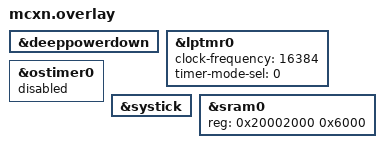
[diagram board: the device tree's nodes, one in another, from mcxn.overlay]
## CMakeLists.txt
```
# SPDX-FileCopyrightText: Copyright 2026 NXP
# SPDX-License-Identifier: Apache-2.0

cmake_minimum_required(VERSION 3.28.0)
find_package(Zephyr REQUIRED HINTS $ENV{ZEPHYR_BASE})
project(s2ram)

target_sources(app PRIVATE src/main.c)
```

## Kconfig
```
# SPDX-FileCopyrightText: Copyright 2026 NXP
# SPDX-License-Identifier: Apache-2.0

mainmenu "NXP MCX suspend-to-RAM sample"

choice
	prompt "Suspend-to-RAM wakeup source"
	default SAMPLE_S2RAM_WAKEUP_TIMER
	help
	  Select how the SoC is woken from suspend-to-RAM (Deep Power Down).

config SAMPLE_S2RAM_WAKEUP_TIMER
	bool "Timed wakeup"
	help
	  Wake after a fixed delay using a low-power timer.

config SAMPLE_S2RAM_WAKEUP_BUTTON
	bool "Button wakeup"
	help
	  Wake on a user button press.

endchoice

config SAMPLE_APP_TEST_CYCLES
	int "Number of suspend-to-RAM cycles to execute"
	range 1 1000
	default 10
	help
	  Number of times the sample suspends to RAM and resumes before it
	  stops. The retained cycle counter is checked against this value so
	  a test harness can confirm every wakeup happened.

source "Kconfig.zephyr"
```

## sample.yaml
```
# SPDX-FileCopyrightText: Copyright 2026 NXP
# SPDX-License-Identifier: Apache-2.0

sample:
  name: Suspend-to-RAM for NXP MCX

common:
  tags:
    - power
    - pm
  platform_allow:
    - frdm_mcxn947/mcxn947/cpu0
    - mcx_n5xx_evk/mcxn547/cpu0
    - mcx_n9xx_evk/mcxn947/cpu0
    - frdm_mcxn236
    - frdm_mcxa153
    - frdm_mcxa156
    - frdm_mcxa344
    - frdm_mcxa266
    - frdm_mcxa346
    - frdm_mcxa366
  integration_platforms:
    - frdm_mcxn947/mcxn947/cpu0
    - frdm_mcxa156
  harness: console
  harness_config:
    type: one_line
    regex:
      - "suspend-to-RAM demo"

tests:
  sample.boards.nxp.mcxn_a.s2ram.timer:
    timeout: 120
    harness_config:
      type: one_line
      regex:
        - "Completed 10 suspend-to-RAM cycles"
    extra_configs:
      - CONFIG_SAMPLE_S2RAM_WAKEUP_TIMER=y
  sample.boards.nxp.mcxn_a.s2ram.button:
    extra_configs:
      - CONFIG_SAMPLE_S2RAM_WAKEUP_BUTTON=y
```

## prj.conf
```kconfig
# SPDX-FileCopyrightText: Copyright 2026 NXP
# SPDX-License-Identifier: Apache-2.0

CONFIG_PM=y
CONFIG_WUC=y
CONFIG_COUNTER=y
CONFIG_COUNTER_MCUX_LPTMR_ALARM=y
```

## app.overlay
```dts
/*
 * SPDX-FileCopyrightText: Copyright 2026 NXP
 *
 * SPDX-License-Identifier: Apache-2.0
 */

/* Suspend-to-RAM (Deep Power Down) is opt-in: the SoC disables it by default.
 * This sample places its working set in retained RAM and arms a wakeup source,
 * so enable the state here.
 */
&deeppowerdown {
	status = "okay";
};

&lptmr0 {
	status = "okay";
	clock-frequency = <16384>;
	timer-mode-sel = <0>;
};

&ostimer0 {
	status = "disabled";
};

&systick {
	status = "okay";
};
```

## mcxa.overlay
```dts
/*
 * SPDX-FileCopyrightText: Copyright 2026 NXP
 *
 * SPDX-License-Identifier: Apache-2.0
 */

/* Suspend-to-RAM (Deep Power Down) is opt-in: the SoC disables it by default.
 * This sample places its working set in retained RAM and arms a wakeup source,
 * so enable the state here.
 */
&deeppowerdown {
	status = "okay";
};

&lptmr0 {
	clock-frequency = <16384>;
	timer-mode-sel = <0>;
	status = "okay";
};

&ostimer0 {
	status = "disabled";
};

&systick {
	status = "okay";
};
```

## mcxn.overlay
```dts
/*
 * SPDX-FileCopyrightText: Copyright 2026 NXP
 *
 * SPDX-License-Identifier: Apache-2.0
 */

/* Suspend-to-RAM (Deep Power Down) is opt-in: the SoC disables it by default.
 * This sample places its working set in retained RAM and arms a wakeup source,
 * so enable the state here.
 */
&deeppowerdown {
	status = "okay";
};

&lptmr0 {
	clock-frequency = <16384>;
	timer-mode-sel = <0>;
	status = "okay";
};

&ostimer0 {
	status = "disabled";
};

&systick {
	status = "okay";
};

/* Constrain zephyr,sram to RAMA1-RAMA3 (24 KB at 0x20002000) so the whole
 * retained working set is both kept across Deep Power Down and kept clear of
 * the boot ROM scratch.
 */
&sram0 {
	reg = <0x20002000 0x6000>;
};
```

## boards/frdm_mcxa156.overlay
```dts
/*
 * SPDX-FileCopyrightText: Copyright 2026 NXP
 *
 * SPDX-License-Identifier: Apache-2.0
 */

&ostimer0 {
	status = "disabled";
};

&systick {
	status = "okay";
};

/* Suspend-to-RAM is opt-in (the SoC disables it by default); enable it here. */
&deeppowerdown {
	status = "okay";
};
```

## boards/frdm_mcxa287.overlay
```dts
/*
 * SPDX-FileCopyrightText: Copyright 2026 NXP
 *
 * SPDX-License-Identifier: Apache-2.0
 */

/* Deep Power Down on MCXAxx7 can retain ONLY SRAM arrays A0 and A3 (per the
 * reference manual, section "Deep Power Down mode"). A1 and A2 lose power in
 * DPD regardless of the VBAT retention config. Constrain zephyr,sram to A3
 * (16 KB at 0x20004000) so the entire retained working set - including the
 * pm_s2ram marker and saved CPU context - lands in a DPD-retainable array.
 */
&sram0 {
	reg = <0x20004000 0x4000>;
};

/* Suspend-to-RAM is opt-in (the SoC disables it by default); enable it here. */
&deeppowerdown {
	status = "okay";
};
```

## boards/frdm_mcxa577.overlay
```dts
/*
 * SPDX-FileCopyrightText: Copyright 2026 NXP
 *
 * SPDX-License-Identifier: Apache-2.0
 */

/* Suspend-to-RAM (Deep Power Down) is opt-in: the SoC disables it by default.
 * This sample places its working set in retained RAM and arms a wakeup source,
 * so enable the state here.
 */
&deeppowerdown {
	status = "okay";
};

&lptmr0 {
	clock-frequency = <16384>;
	timer-mode-sel = <0>;
	status = "okay";
};

&ostimer0 {
	status = "disabled";
};

&systick {
	status = "okay";
};

/* Deep Power Down on MCXAxx7 can retain ONLY SRAM arrays A0 and A3 (per the
 * reference manual, section "Deep Power Down mode"). A1 and A2 lose power in
 * DPD regardless of the VBAT retention config. Constrain zephyr,sram to A3
 * (16 KB at 0x20004000) so the entire retained working set - including the
 * pm_s2ram marker and saved CPU context - lands in a DPD-retainable array.
 */
&sram0 {
	reg = <0x20004000 0x4000>;
};
```

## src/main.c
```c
/*
 * SPDX-FileCopyrightText: Copyright 2026 NXP
 *
 * SPDX-License-Identifier: Apache-2.0
 */

#include <zephyr/kernel.h>
#include <zephyr/device.h>
#include <zephyr/pm/pm.h>
#include <zephyr/pm/policy.h>
#include <zephyr/drivers/wuc.h>

#define WAKEUP_DELAY_S 3U

#define APP_STACK_SIZE 2048
#define APP_PRIORITY   5

/* Incremented before every suspend. Its value surviving the suspend/resume
 * cycle proves the RAM was retained while the CORE domain was powered down.
 */
static uint32_t cycles;

#define CONSOLE_NODE   DT_CHOSEN(zephyr_console)
#define CONSOLE_PARENT DT_PARENT(CONSOLE_NODE)

static const struct device *const console_dev = DEVICE_DT_GET(CONSOLE_NODE);
#if DT_NODE_HAS_COMPAT(CONSOLE_PARENT, nxp_lp_flexcomm)
#define HAS_FLEXCOMM_PARENT 1
static const struct device *const flexcomm_dev = DEVICE_DT_GET(CONSOLE_PARENT);
#endif

/*
 * Deep Power Down resets every CORE-domain peripheral. On a transparent resume
 * the SoC restores the CPU context and clocks, but the console UART driver has
 * no device pm hooks, so re-initialise it before printing. Three clock gates
 * that Deep Power Down switched off have to be re-opened, bottom up, before the
 * console can drive its pins again:
 *
 *   1. the PORT pin-mux controllers - their gate must be on for the LPUART
 *      pinctrl re-apply (step 3) to actually reach the pad-mux registers,
 *   2. the parent LP_FLEXCOMM - its init re-enables the peripheral clock gate
 *      and re-selects LPUART mode, then
 *   3. the LPUART itself - its init re-applies pinctrl and the baud/format.
 *
 * device_init() is a no-op on an already-initialised device, so clear the
 * initialised flag to force each driver to re-run its init against the reset
 * hardware. (A production driver would do this through a PM_DEVICE_ACTION_RESUME
 * handler instead.) printk keeps working once the LPUART is back: its console
 * output hook still points at the same device.
 */
#define REINIT_DEVICE(dev)				\
	do {						\
		(dev)->state->initialized = false;	\
		(void)device_init(dev);			\
	} while (0)

#define REINIT_PORT(node_id) REINIT_DEVICE(DEVICE_DT_GET(node_id));

static void resume_console(void)
{
	/* Re-open every PORT pin-mux clock gate that Deep Power Down closed. */
	DT_FOREACH_STATUS_OKAY(nxp_port_pinmux, REINIT_PORT)

#ifdef HAS_FLEXCOMM_PARENT
	REINIT_DEVICE(flexcomm_dev);
#endif
	REINIT_DEVICE(console_dev);
}

#if defined(CONFIG_SAMPLE_S2RAM_WAKEUP_BUTTON)
/* In real-world applications, the button's wake-up event should be handled
 * via the driver hook, allowing the application to directly wait for input
 * events without needing to consider the existence of WUU. However, due to
 * the current lack of hook handling, we use the PM notifier to handle the
 * wake-up event.
 */
static K_SEM_DEFINE(button_wakeup, 0, 1);
static const struct wuc_dt_spec button = WUC_DT_SPEC_GET(DT_ALIAS(wakeup_button));

static void on_pm_state_exit(enum pm_state state)
{
	if (state == PM_STATE_SUSPEND_TO_RAM) {
		k_sem_give(&button_wakeup);
	}
}

static struct pm_notifier button_pm_notifier = {
	.state_exit = on_pm_state_exit,
};
#else
/* The timer variant relies on LPTMR0, which the counter driver arms as a
 * wakeup source on its own.
 */
#endif /* CONFIG_SAMPLE_S2RAM_WAKEUP_BUTTON */

static void app_thread(void *p1, void *p2, void *p3)
{
	ARG_UNUSED(p1);
	ARG_UNUSED(p2);
	ARG_UNUSED(p3);

	while (cycles < CONFIG_SAMPLE_APP_TEST_CYCLES) {
		cycles++;

#if defined(CONFIG_SAMPLE_S2RAM_WAKEUP_BUTTON)
		printk("Entering suspend-to-RAM (cycle %u/%u); press SW2 to wake\n", cycles,
		       CONFIG_SAMPLE_APP_TEST_CYCLES);
#else
		printk("Entering suspend-to-RAM (cycle %u/%u); wake in %u s\n", cycles,
		       CONFIG_SAMPLE_APP_TEST_CYCLES, WAKEUP_DELAY_S);
#endif

		/* Let the UART finish shifting out the line above before DPD cuts its clock. */
		k_busy_wait(2000);

#if defined(CONFIG_SAMPLE_S2RAM_WAKEUP_BUTTON) &&				\
	(defined(CONFIG_SOC_SERIES_MCXAXX6) || defined(CONFIG_SOC_SERIES_MCXAXX7))
		/* MCXAxx6 / MCXAxx7 clear the WUU config on the DPD wakeup reset,
		 * so re-arm the button before each entry.
		 */
		(void)wuc_enable_wakeup_source_dt(&button);
#endif

		pm_state_force(0U, &(struct pm_state_info){PM_STATE_SUSPEND_TO_RAM, 0, 0});
#if defined(CONFIG_SAMPLE_S2RAM_WAKEUP_BUTTON)
		/* Block until SW2 wakes the SoC; the PM notifier gives this. */
		k_sem_take(&button_wakeup, K_FOREVER);
#else
		k_sleep(K_SECONDS(WAKEUP_DELAY_S));
#endif

		resume_console();
		printk("Resumed from suspend-to-RAM; retained counter is %u\n", cycles);
	}

	/* All threads are now idle for good, but every PM state is locked, so the
	 * SoC stays awake and the board remains debuggable after the test.
	 */
	printk("Completed %u suspend-to-RAM cycles\n", cycles);
}

K_THREAD_STACK_DEFINE(app_stack, APP_STACK_SIZE);
static struct k_thread app_thread_data;

int main(void)
{
	printk("%s suspend-to-RAM demo\n", CONFIG_BOARD);
	printk("Retained S2RAM cycle counter: %u\n", cycles);

	pm_policy_state_lock_get(PM_STATE_RUNTIME_IDLE, PM_ALL_SUBSTATES);
	pm_policy_state_lock_get(PM_STATE_SUSPEND_TO_IDLE, PM_ALL_SUBSTATES);
	pm_policy_state_lock_get(PM_STATE_STANDBY, PM_ALL_SUBSTATES);
	pm_policy_state_lock_get(PM_STATE_SUSPEND_TO_RAM, PM_ALL_SUBSTATES);

#if defined(CONFIG_SAMPLE_S2RAM_WAKEUP_BUTTON)
	/* Arm the button as the wakeup source. */
	pm_notifier_register(&button_pm_notifier);
	(void)wuc_enable_wakeup_source_dt(&button);
#endif

	k_thread_create(&app_thread_data, app_stack, APP_STACK_SIZE, app_thread,
			NULL, NULL, NULL, APP_PRIORITY, 0, K_NO_WAIT);

	return 0;
}
```
